# TMS320F280049 register map
Vendor: Texas Instruments; Series: C2000 F28004x; File version: 0.2.0-generated
Registers are 16-bit, read-write, reset 0x0 unless marked. A register's access mark holds for its fields unless they carry their own. Offsets are from the block's base; [hi:lo] are bit positions; {n}, {i} and the like mark numbered series.

## VCU — VCU Registers
Base 0x00002400
{0x0+4i} VR{i} 32-bit (i=0..8) — General Purpose 32-bit registers
0x24 VT0 32-bit — Transition Bit register
0x28 VT1 32-bit — Transition Bit register
0x40 VSTATUS 32-bit — VCU Status Register
0x44 VCRC 32-bit — CRC Result register for un-secured memories

## CLA1REGS — CLA2 Registers
Base 0x00002800
0x00 MVECT1 — Task 1 vector
0x02 MVECT2 — Task 2 vector
0x04 MVECT3 — Task 3 vector
0x06 MVECT4 — Task 4 vector
0x08 MVECT5 — Task 5 vector
0x0A MVECT6 — Task 6 vector
0x0C MVECT7 — Task 7 vector
0x0E MVECT8 — Task 8 vector
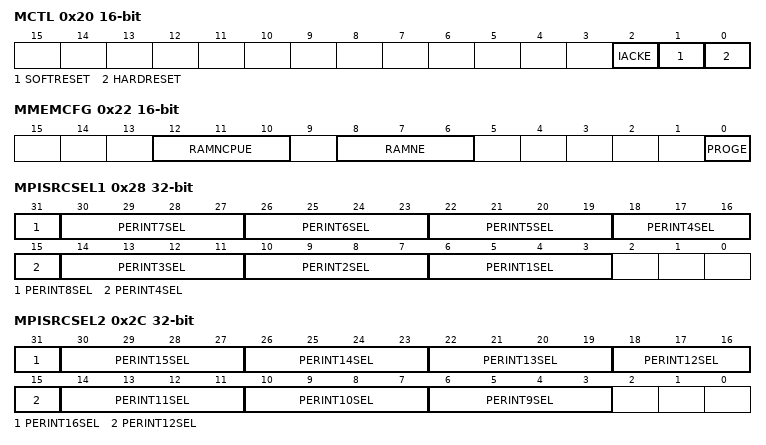
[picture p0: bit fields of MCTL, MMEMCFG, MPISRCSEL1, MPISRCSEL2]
0x20 MCTL — CLA control
  [2] IACKE — IACK enable
  [1] SOFTRESET
  [0] HARDRESET
0x22 MMEMCFG — CLA memory configuration
  [12:10] RAMNCPUE — Data RAM CPU Access Enable
  [8:6] RAMNE — Data RAM Enable
  [0] PROGE — Program memory enable
0x28 MPISRCSEL1 32-bit — CLA interrupt source select 1
  [31] PERINT8SEL — Task 8 Peripheral Interrupt Input Select
  [4n+2:4n-1] PERINT{n}SEL (n=1..7) — Task {n} Peripheral Interrupt Input Select
0x2C MPISRCSEL2 32-bit — CLA interrupt source select 2
  [31] PERINT16SEL — Task 16 Peripheral Interrupt Input Select
  [4n-30:4n-33] PERINT{n}SEL (n=9..15) — Task {n} Peripheral Interrupt Input Select
0x36 MVECTBGRNDACTIVE — Active register for MVECTBGRND
  [15] I16 — Active register for the Background Task Vector
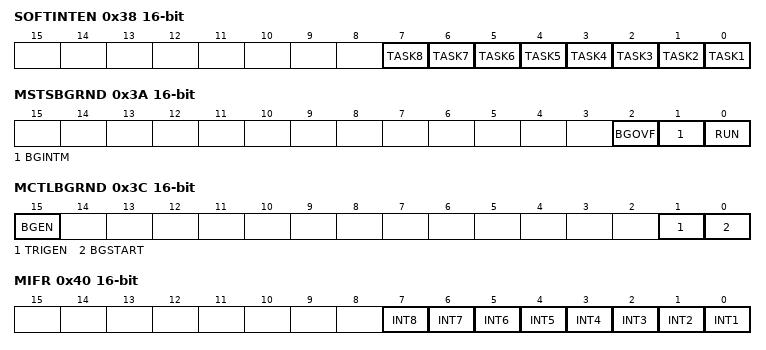
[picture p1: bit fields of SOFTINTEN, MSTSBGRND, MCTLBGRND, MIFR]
0x38 SOFTINTEN — CLA Software Interrupt Enable Register
  [n-1] TASK{n} (n=1..8) — Configure Software Interrupt or End of Task {n} interrupt
0x3A MSTSBGRND — Status register for the background task
  [2] BGOVF — Background task hardware trigger overflow
  [1] BGINTM — Indicates whether background task can be interrupted
  [0] RUN — Background task run status bit
0x3C MCTLBGRND — Control register for the background task
  [15] BGEN — Enable Background task
  [1] TRIGEN — Background task hardware trigger enable
  [0] BGSTART — Background task start bit
0x3E MVECTBGRND — Vector for the background task
  [15] I16 — Background task vector
0x40 MIFR — CLA interrupt flag
  [n-1] INT{n} (n=1..8) — Interrupt {n} flag bit
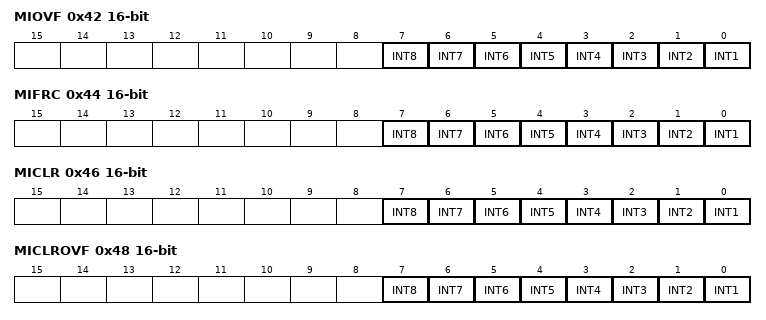
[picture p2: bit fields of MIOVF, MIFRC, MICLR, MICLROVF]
0x42 MIOVF — CLA interrupt overflow flag
  [n-1] INT{n} (n=1..8) — Interrupt {n} overflow bit
0x44 MIFRC — CLA interrupt force
  [n-1] INT{n} (n=1..8) — Interrupt {n} force bit
0x46 MICLR — CLA interrupt flag clear
  [n-1] INT{n} (n=1..8) — Interrupt {n} clear bit
0x48 MICLROVF — CLA interrupt overflow flag clear
  [n-1] INT{n} (n=1..8) — Interrupt {n} overflow clear bit
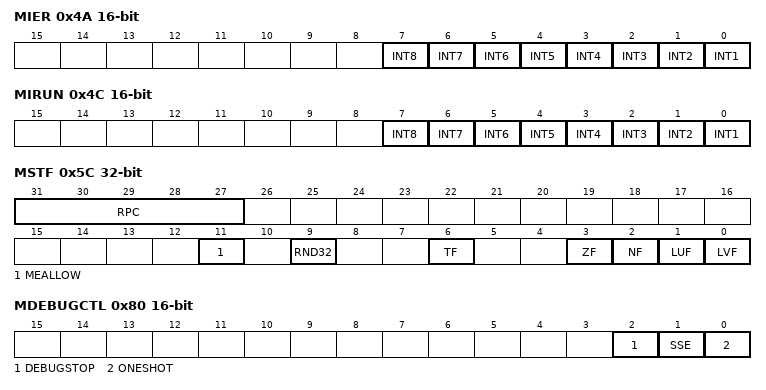
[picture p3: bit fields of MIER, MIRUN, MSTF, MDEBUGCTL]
0x4A MIER — CLA interrupt enable
  [n-1] INT{n} (n=1..8) — Interrupt {n} enable bit
0x4C MIRUN — CLA interrupt run status
  [n-1] INT{n} (n=1..8) — Interrupt {n} run status
0x50 MPC — CLA program counter
0x54 MAR0 — CLA auxiliary register 0
0x56 MAR1 — CLA auxiliary register 1
0x5C MSTF 32-bit — CLA floating-point status register
  [31:27] RPC — Return PC
  [11] MEALLOW — Protected write
  [9] RND32 — Rounding mode
  [6] TF — Test flag
  [3] ZF — Zero flag
  [2] NF — Negative flag
  [1] LUF — Underflow flag
  [0] LVF — Overflow flag
{0x60+8i} MR{i} 32-bit (i=0..3) — CLA result register {i}
0x80 MDEBUGCTL — CLA Debug Control Register
  [2] DEBUGSTOP — Debug stop bit
  [1] SSE — Single Step Enable bit
  [0] ONESHOT — One Shot Mode bit
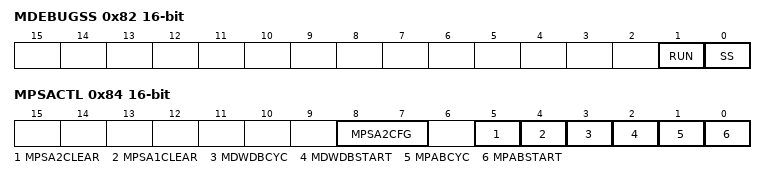
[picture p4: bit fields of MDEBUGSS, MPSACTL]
0x82 MDEBUGSS — CLA Debug Step Register
  [1] RUN — Run bit
  [0] SS — Single Step Command bit
0x84 MPSACTL — PSA Control Register
  [8:7] MPSA2CFG — PSA2 Polynomial Configuration
  [5] MPSA2CLEAR — PSA2 Clear
  [4] MPSA1CLEAR — PSA1 Clear
  [3] MDWDBCYC — DWDB logging into PSA2 is on every cycle
  [2] MDWDBSTART — Start logging DWDB onto PSA2
  [1] MPABCYC — PAB logging into PSA1 is on every cycle or when PAB changes
  [0] MPABSTART — Start logging PAB onto PSA1
0x88 MPSA1 32-bit — CLA PSA1 Register
0x8C MPSA2 32-bit — CLA PSA2 Register
